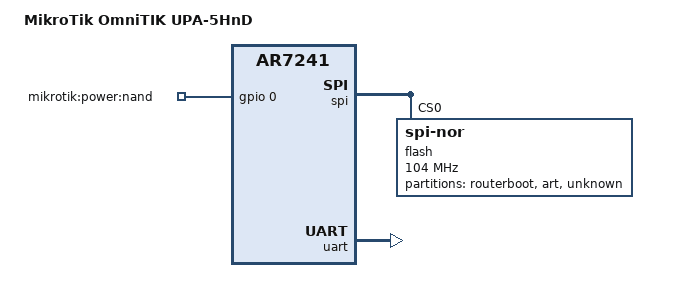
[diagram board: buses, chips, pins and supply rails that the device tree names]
// SPDX-License-Identifier: GPL-2.0-or-later OR MIT
/dts-v1/;

#include <dt-bindings/gpio/gpio.h>
#include <dt-bindings/input/input.h>

#include "ar7241.dtsi"

/ {
	compatible = "mikrotik,mikrotik_omnitik-upda-5hnd", "qca,ar7241";
	model = "MikroTik OmniTIK UPA-5HnD";

	aliases {
		label-mac-device = &eth0;
		led-boot = &led_act;
		led-failsafe = &led_act;
		led-upgrade = &led_act;
		serial0 = &uart;
	};

	chosen {
		bootargs = "console=ttyS0,115200n8";
	};

	gpio-export {
		compatible = "gpio-export";

		gpio_nand_power {
			gpio-export,name = "mikrotik:power:nand";
			gpio-export,output = <0>;
			gpios = <&gpio 0 GPIO_ACTIVE_HIGH>;
		};
	};
};

&spi {
	status = "okay";

	cs-gpios = <0>, <0>;
	num-cs = <2>;

	flash@0 {
		compatible = "jedec,spi-nor";
		reg = <0>;
		spi-max-frequency = <104000000>;

		partitions {
			compatible = "fixed-partitions";
			#address-cells = <1>;
			#size-cells = <1>;

			partition@0 {
				label = "routerboot";
				reg = <0x000000 0x00b000>;
				read-only;
			};

			art: partition@b000 {
				label = "art";
				reg = <0x000b000 0x001000>;
				read-only;
			};

			partition@c000 {
				label = "unknown";
				reg = <0x000c000 0x003000>;
				read-only;
			};
		};
	};
};


&uart {
	status = "okay";
};
